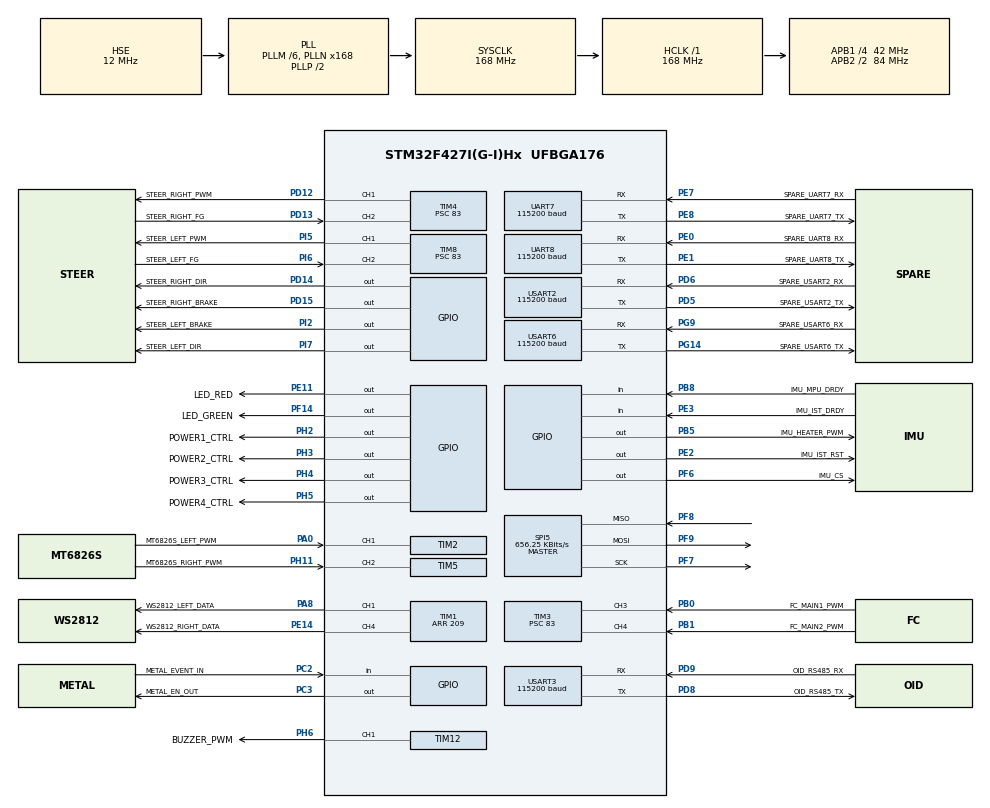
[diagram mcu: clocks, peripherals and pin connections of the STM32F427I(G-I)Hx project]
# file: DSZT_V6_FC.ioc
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Dma.Request0=TIM1_CH1
Dma.Request1=TIM1_CH4/TRIG/COM
Dma.TIM1_CH1.0.Direction=DMA_MEMORY_TO_PERIPH
Dma.TIM1_CH1.0.FIFOMode=DMA_FIFOMODE_DISABLE
Dma.TIM1_CH1.0.Instance=DMA2_Stream3
Dma.TIM1_CH1.0.MemDataAlignment=DMA_MDATAALIGN_HALFWORD
Dma.TIM1_CH1.0.MemInc=DMA_MINC_ENABLE
Dma.TIM1_CH1.0.Mode=DMA_NORMAL
Dma.TIM1_CH1.0.PeriphDataAlignment=DMA_PDATAALIGN_HALFWORD
Dma.TIM1_CH1.0.PeriphInc=DMA_PINC_DISABLE
Dma.TIM1_CH1.0.Priority=DMA_PRIORITY_HIGH
Dma.TIM1_CH4/TRIG/COM.1.Direction=DMA_MEMORY_TO_PERIPH
Dma.TIM1_CH4/TRIG/COM.1.FIFOMode=DMA_FIFOMODE_DISABLE
Dma.TIM1_CH4/TRIG/COM.1.Instance=DMA2_Stream4
Dma.TIM1_CH4/TRIG/COM.1.MemDataAlignment=DMA_MDATAALIGN_HALFWORD
Dma.TIM1_CH4/TRIG/COM.1.MemInc=DMA_MINC_ENABLE
Dma.TIM1_CH4/TRIG/COM.1.Mode=DMA_NORMAL
Dma.TIM1_CH4/TRIG/COM.1.PeriphDataAlignment=DMA_PDATAALIGN_HALFWORD
Dma.TIM1_CH4/TRIG/COM.1.PeriphInc=DMA_PINC_DISABLE
Dma.TIM1_CH4/TRIG/COM.1.Priority=DMA_PRIORITY_HIGH
FREERTOS.INCLUDE_vTaskDelayUntil=1
FREERTOS.Tasks01=defaultTask,0,1024,StartDefaultTask,Default,NULL,Dynamic,NULL,NULL
FREERTOS.configENABLE_FPU=1
FREERTOS.configMAX_TASK_NAME_LEN=32
FREERTOS.configTOTAL_HEAP_SIZE=30000
FREERTOS.configUSE_COUNTING_SEMAPHORES=1
FREERTOS.configUSE_POSIX_ERRNO=0
FREERTOS.configUSE_TIMERS=0
Mcu.Family=STM32F4
Mcu.Name=STM32F427I(G-I)Hx
Mcu.Package=UFBGA176
NVIC.DMA2_Stream3_IRQn=true\:5\:0\:false\:false\:true\:true\:true\:true\:true
NVIC.DMA2_Stream4_IRQn=true\:5\:0\:false\:false\:true\:true\:true\:true\:true
NVIC.PriorityGroup=NVIC_PRIORITYGROUP_4
NVIC.TIM2_IRQn=true\:5\:0\:false\:false\:true\:true\:true\:true\:true
NVIC.TIM3_IRQn=true\:5\:0\:false\:false\:true\:true\:true\:true\:true
NVIC.TIM4_IRQn=true\:5\:0\:false\:false\:true\:true\:true\:true\:true
NVIC.TIM5_IRQn=true\:5\:0\:false\:false\:true\:true\:true\:true\:true
NVIC.TIM6_DAC_IRQn=true\:15\:0\:false\:false\:true\:false\:false\:true\:true
NVIC.TIM8_CC_IRQn=true\:5\:0\:false\:false\:true\:true\:true\:true\:true
NVIC.TimeBase=TIM6_DAC_IRQn
NVIC.TimeBaseIP=TIM6
NVIC.UART7_IRQn=true\:5\:0\:false\:false\:true\:true\:true\:true\:true
NVIC.USART3_IRQn=true\:5\:0\:false\:false\:true\:true\:true\:true\:true
PA0/WKUP.GPIO_Label=MT6826S_LEFT_PWM
PA0/WKUP.Signal=S_TIM2_CH1_ETR
PA13.Mode=Serial_Wire
PA13.Signal=SYS_JTMS-SWDIO
PA14.Mode=Serial_Wire
PA14.Signal=SYS_JTCK-SWCLK
PA8.GPIO_Label=WS2812_LEFT_DATA
PA8.GPIO_Speed=GPIO_SPEED_FREQ_VERY_HIGH
PA8.Signal=S_TIM1_CH1
PB0.GPIO_Label=FC_MAIN1_PWM
PB0.GPIO_PuPd=GPIO_PULLDOWN
PB0.Signal=S_TIM3_CH3
PB1.GPIO_Label=FC_MAIN2_PWM
PB1.GPIO_PuPd=GPIO_PULLDOWN
PB1.Signal=S_TIM3_CH4
PB5.GPIO_Label=IMU_HEATER_PWM
PB5.GPIO_OutputLevel=GPIO_PIN_RESET
PB5.Signal=GPIO_Output
PB8.GPIO_Label=IMU_MPU_DRDY
PB8.Signal=GPIO_Input
PC2.GPIO_Label=METAL_EVENT_IN
PC2.Signal=GPIO_Input
PC3.GPIO_Label=METAL_EN_OUT
PC3.GPIO_OutputLevel=GPIO_PIN_RESET
PC3.Signal=GPIO_Output
PD12.GPIO_Label=STEER_RIGHT_PWM
PD12.Signal=S_TIM4_CH1
PD13.GPIO_Label=STEER_RIGHT_FG
PD13.Signal=S_TIM4_CH2
PD14.GPIO_Label=STEER_RIGHT_DIR
PD14.GPIO_ModeDefaultOutputPP=GPIO_MODE_OUTPUT_OD
PD14.GPIO_PuPd=GPIO_NOPULL
PD14.Signal=GPIO_Output
PD15.GPIO_Label=STEER_RIGHT_BRAKE
PD15.GPIO_ModeDefaultOutputPP=GPIO_MODE_OUTPUT_OD
PD15.GPIO_PuPd=GPIO_NOPULL
PD15.Signal=GPIO_Output
PD5.GPIO_Label=SPARE_USART2_TX
PD5.Mode=Asynchronous
PD5.Signal=USART2_TX
PD6.GPIO_Label=SPARE_USART2_RX
PD6.Mode=Asynchronous
PD6.Signal=USART2_RX
PD8.GPIO_Label=OID_RS485_TX
PD8.Mode=Asynchronous
PD8.Signal=USART3_TX
PD9.GPIO_Label=OID_RS485_RX
PD9.Mode=Asynchronous
PD9.Signal=USART3_RX
PE0.GPIO_Label=SPARE_UART8_RX
PE0.Mode=Asynchronous
PE0.Signal=UART8_RX
PE1.GPIO_Label=SPARE_UART8_TX
PE1.Mode=Asynchronous
PE1.Signal=UART8_TX
PE11.GPIO_Label=LED_RED
PE11.GPIO_OutputLevel=GPIO_PIN_SET
PE11.Signal=GPIO_Output
PE14.GPIO_Label=WS2812_RIGHT_DATA
PE14.GPIO_Speed=GPIO_SPEED_FREQ_VERY_HIGH
PE14.Signal=S_TIM1_CH4
PE2.GPIO_Label=IMU_IST_RST
PE2.GPIO_OutputLevel=GPIO_PIN_SET
PE2.Signal=GPIO_Output
PE3.GPIO_Label=IMU_IST_DRDY
PE3.Signal=GPIO_Input
PE7.GPIO_Label=SPARE_UART7_RX
PE7.Mode=Asynchronous
PE7.Signal=UART7_RX
PE8.GPIO_Label=SPARE_UART7_TX
PE8.Mode=Asynchronous
PE8.Signal=UART7_TX
PF14.GPIO_Label=LED_GREEN
PF14.GPIO_OutputLevel=GPIO_PIN_SET
PF14.Signal=GPIO_Output
PF6.GPIO_Label=IMU_CS
PF6.GPIO_OutputLevel=GPIO_PIN_SET
PF6.Signal=GPIO_Output
PF7.Mode=Full_Duplex_Master
PF7.Signal=SPI5_SCK
PF8.Mode=Full_Duplex_Master
PF8.Signal=SPI5_MISO
PF9.Mode=Full_Duplex_Master
PF9.Signal=SPI5_MOSI
PG14.GPIO_Label=SPARE_USART6_TX
PG14.Mode=Asynchronous
PG14.Signal=USART6_TX
PG9.GPIO_Label=SPARE_USART6_RX
PG9.Mode=Asynchronous
PG9.Signal=USART6_RX
PH0/OSC_IN.Mode=HSE-External-Oscillator
PH0/OSC_IN.Signal=RCC_OSC_IN
PH1/OSC_OUT.Mode=HSE-External-Oscillator
PH1/OSC_OUT.Signal=RCC_OSC_OUT
PH11.GPIO_Label=MT6826S_RIGHT_PWM
PH11.Signal=S_TIM5_CH2
PH2.GPIO_Label=POWER1_CTRL
PH2.PinState=GPIO_PIN_SET
PH2.Signal=GPIO_Output
PH3.GPIO_Label=POWER2_CTRL
PH3.PinState=GPIO_PIN_SET
PH3.Signal=GPIO_Output
PH4.GPIO_Label=POWER3_CTRL
PH4.PinState=GPIO_PIN_SET
PH4.Signal=GPIO_Output
PH5.GPIO_Label=POWER4_CTRL
PH5.PinState=GPIO_PIN_SET
PH5.Signal=GPIO_Output
PH6.GPIO_Label=BUZZER_PWM
PH6.GPIO_Speed=GPIO_SPEED_FREQ_HIGH
PH6.Signal=S_TIM12_CH1
PI2.GPIO_Label=STEER_LEFT_BRAKE
PI2.GPIO_ModeDefaultOutputPP=GPIO_MODE_OUTPUT_OD
PI2.GPIO_PuPd=GPIO_NOPULL
PI2.Signal=GPIO_Output
PI5.GPIO_Label=STEER_LEFT_PWM
PI5.Signal=S_TIM8_CH1
PI6.GPIO_Label=STEER_LEFT_FG
PI6.Signal=S_TIM8_CH2
PI7.GPIO_Label=STEER_LEFT_DIR
PI7.GPIO_ModeDefaultOutputPP=GPIO_MODE_OUTPUT_OD
PI7.GPIO_PuPd=GPIO_NOPULL
PI7.Signal=GPIO_Output
ProjectManager.HeapSize=0x200
ProjectManager.StackSize=0x400
ProjectManager.TargetToolchain=MDK-ARM V5.32
RCC.48MHZClocksFreq_Value=48000000
RCC.AHBFreq_Value=168000000
RCC.APB1CLKDivider=RCC_HCLK_DIV4
RCC.APB1Freq_Value=42000000
RCC.APB1TimFreq_Value=84000000
RCC.APB2CLKDivider=RCC_HCLK_DIV2
RCC.APB2Freq_Value=84000000
RCC.APB2TimFreq_Value=168000000
RCC.CortexFreq_Value=168000000
RCC.HCLKFreq_Value=168000000
RCC.HSE_VALUE=12000000
RCC.HSI_VALUE=16000000
RCC.LSE_VALUE=32768
RCC.PLLM=6
RCC.PLLN=168
RCC.PLLQ=7
RCC.PLLSourceVirtual=RCC_PLLSOURCE_HSE
RCC.SYSCLKFreq_VALUE=168000000
RCC.SYSCLKSource=RCC_SYSCLKSOURCE_PLLCLK
RCC.VCOOutputFreq_Value=336000000
SH.S_TIM12_CH1.0=TIM12_CH1,PWM Generation1 CH1
SH.S_TIM1_CH1.0=TIM1_CH1,PWM Generation1 CH1
SH.S_TIM1_CH4.0=TIM1_CH4,PWM Generation4 CH4
SH.S_TIM2_CH1_ETR.0=TIM2_CH1,Input_Capture1_from_TI1
SH.S_TIM3_CH3.0=TIM3_CH3,Input_Capture3_from_TI3
SH.S_TIM3_CH4.0=TIM3_CH4,Input_Capture4_from_TI4
SH.S_TIM4_CH1.0=TIM4_CH1,PWM Generation1 CH1
SH.S_TIM4_CH2.0=TIM4_CH2,Input_Capture2_from_TI2
SH.S_TIM5_CH2.0=TIM5_CH2,Input_Capture2_from_TI2
SH.S_TIM8_CH1.0=TIM8_CH1,PWM Generation1 CH1
SH.S_TIM8_CH2.0=TIM8_CH2,Input_Capture2_from_TI2
SPI5.BaudRatePrescaler=SPI_BAUDRATEPRESCALER_128
SPI5.CalculateBaudRate=656.25 KBits/s
SPI5.Direction=SPI_DIRECTION_2LINES
SPI5.Mode=SPI_MODE_MASTER
SPI5.VirtualType=VM_MASTER
TIM1.Channel-PWM\ Generation1\ CH1=TIM_CHANNEL_1
TIM1.Channel-PWM\ Generation4\ CH4=TIM_CHANNEL_4
TIM1.Period=209
TIM12.AutoReloadPreload=TIM_AUTORELOAD_PRELOAD_DISABLE
TIM12.Channel-PWM\ Generation1\ CH1=TIM_CHANNEL_1
TIM12.ClockDivision=TIM_CLOCKDIVISION_DIV1
TIM12.CounterMode=TIM_COUNTERMODE_UP
TIM12.OCFastMode_PWM-PWM\ Generation1\ CH1=TIM_OCFAST_DISABLE
TIM12.Period=31110
TIM12.Prescaler=0
TIM12.Pulse-PWM\ Generation1\ CH1=0
TIM2.AutoReloadPreload=TIM_AUTORELOAD_PRELOAD_DISABLE
TIM2.Channel-Input_Capture1_from_TI1=TIM_CHANNEL_1
TIM2.ClockDivision=TIM_CLOCKDIVISION_DIV1
TIM2.CounterMode=TIM_COUNTERMODE_UP
TIM2.Period=4294967295
TIM2.Prescaler=83
TIM3.AutoReloadPreload=TIM_AUTORELOAD_PRELOAD_DISABLE
TIM3.Channel-Input_Capture3_from_TI3=TIM_CHANNEL_3
TIM3.Channel-Input_Capture4_from_TI4=TIM_CHANNEL_4
TIM3.ClockDivision=TIM_CLOCKDIVISION_DIV1
TIM3.CounterMode=TIM_COUNTERMODE_UP
TIM3.Period=65535
TIM3.Prescaler=83
TIM4.AutoReloadPreload=TIM_AUTORELOAD_PRELOAD_DISABLE
TIM4.Channel-Input_Capture2_from_TI2=TIM_CHANNEL_2
TIM4.Channel-PWM\ Generation1\ CH1=TIM_CHANNEL_1
TIM4.ClockDivision=TIM_CLOCKDIVISION_DIV1
TIM4.CounterMode=TIM_COUNTERMODE_UP
TIM4.OCFastMode_PWM-PWM\ Generation1\ CH1=TIM_OCFAST_DISABLE
TIM4.Period=39
TIM4.Prescaler=83
TIM4.Pulse-PWM\ Generation1\ CH1=40
TIM5.Channel-Input_Capture2_from_TI2=TIM_CHANNEL_2
TIM5.Period=4294967295
TIM5.Prescaler=83
TIM8.AutoReloadPreload=TIM_AUTORELOAD_PRELOAD_DISABLE
TIM8.Channel-Input_Capture2_from_TI2=TIM_CHANNEL_2
TIM8.Channel-PWM\ Generation1\ CH1=TIM_CHANNEL_1
TIM8.ClockDivision=TIM_CLOCKDIVISION_DIV1
TIM8.CounterMode=TIM_COUNTERMODE_UP
TIM8.OCFastMode_PWM-PWM\ Generation1\ CH1=TIM_OCFAST_DISABLE
TIM8.Period=39
TIM8.Prescaler=83
TIM8.Pulse-PWM\ Generation1\ CH1=40
UART7.BaudRate=115200
UART7.VirtualMode=Asynchronous
UART8.BaudRate=115200
UART8.VirtualMode=Asynchronous
USART2.BaudRate=115200
USART2.VirtualMode=VM_ASYNC
USART3.BaudRate=115200
USART3.VirtualMode=VM_ASYNC
USART6.BaudRate=115200
USART6.VirtualMode=VM_ASYNC
VP_FREERTOS_VS_CMSIS_V1.Mode=CMSIS_V1
VP_SYS_VS_tim6.Mode=TIM6
VP_TIM1_VS_ClockSourceINT.Mode=Internal
board=custom

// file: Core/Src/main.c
/* USER CODE BEGIN Header */
/**
  ******************************************************************************
  * @file           : main.c
  * @brief          : Main program body
  ******************************************************************************
  * @attention
  *
  * Copyright (c) 2026 STMicroelectronics.
  * All rights reserved.
  *
  * This software is licensed under terms that can be found in the LICENSE file
  * in the root directory of this software component.
  * If no LICENSE file comes with this software, it is provided AS-IS.
  *
  ******************************************************************************
  */
/* USER CODE END Header */
#include "main.h"
#include "cmsis_os.h"
#include "dma.h"
#include "spi.h"
#include "tim.h"
#include "usart.h"
#include "gpio.h"

/* USER CODE BEGIN Includes */
#include "robot.h"
/* USER CODE END Includes */

void SystemClock_Config(void);
void MX_FREERTOS_Init(void);

int main(void)
{

  /* MCU Configuration--------------------------------------------------------*/

  /* Reset of all peripherals, Initializes the Flash interface and the Systick. */
  HAL_Init();

  /* Configure the system clock */
  SystemClock_Config();

  /* Initialize all configured peripherals */
  MX_GPIO_Init();
  MX_DMA_Init();
  MX_SPI5_Init();
  MX_TIM1_Init();
  MX_TIM2_Init();
  MX_TIM3_Init();
  MX_TIM4_Init();
  MX_TIM5_Init();
  MX_TIM8_Init();
  MX_TIM12_Init();
  MX_UART7_Init();
  MX_UART8_Init();
  MX_USART2_UART_Init();
  MX_USART3_UART_Init();
  MX_USART6_UART_Init();
  /* USER CODE BEGIN 2 */
  RobotInit();
  /* USER CODE END 2 */

  /* Call init function for freertos objects (in cmsis_os2.c) */
  MX_FREERTOS_Init();

  /* Start scheduler */
  osKernelStart();

  /* We should never get here as control is now taken by the scheduler */

  /* Infinite loop */
  while (1)
  {

  }
}

void SystemClock_Config(void)
{
  RCC_OscInitTypeDef RCC_OscInitStruct = {0};
  RCC_ClkInitTypeDef RCC_ClkInitStruct = {0};

  /** Configure the main internal regulator output voltage
  */
  __HAL_RCC_PWR_CLK_ENABLE();
  __HAL_PWR_VOLTAGESCALING_CONFIG(PWR_REGULATOR_VOLTAGE_SCALE1);

  /** Initializes the RCC Oscillators according to the specified parameters
  * in the RCC_OscInitTypeDef structure.
  */
  RCC_OscInitStruct.OscillatorType = RCC_OSCILLATORTYPE_HSE;
  RCC_OscInitStruct.HSEState = RCC_HSE_ON;
  RCC_OscInitStruct.PLL.PLLState = RCC_PLL_ON;
  RCC_OscInitStruct.PLL.PLLSource = RCC_PLLSOURCE_HSE;
  RCC_OscInitStruct.PLL.PLLM = 6;
  RCC_OscInitStruct.PLL.PLLN = 168;
  RCC_OscInitStruct.PLL.PLLP = RCC_PLLP_DIV2;
  RCC_OscInitStruct.PLL.PLLQ = 7;
  if (HAL_RCC_OscConfig(&RCC_OscInitStruct) != HAL_OK)
  {
    Error_Handler();
  }

  /** Initializes the CPU, AHB and APB buses clocks
  */
  RCC_ClkInitStruct.ClockType = RCC_CLOCKTYPE_HCLK|RCC_CLOCKTYPE_SYSCLK
                              |RCC_CLOCKTYPE_PCLK1|RCC_CLOCKTYPE_PCLK2;
  RCC_ClkInitStruct.SYSCLKSource = RCC_SYSCLKSOURCE_PLLCLK;
  RCC_ClkInitStruct.AHBCLKDivider = RCC_SYSCLK_DIV1;
  RCC_ClkInitStruct.APB1CLKDivider = RCC_HCLK_DIV4;
  RCC_ClkInitStruct.APB2CLKDivider = RCC_HCLK_DIV2;

  if (HAL_RCC_ClockConfig(&RCC_ClkInitStruct, FLASH_LATENCY_5) != HAL_OK)
  {
    Error_Handler();
  }
}

void HAL_TIM_PeriodElapsedCallback(TIM_HandleTypeDef *htim)
{
  if (htim->Instance == TIM6)
  {
    HAL_IncTick();
  }
}

void Error_Handler(void)
{
  __disable_irq();
  while (1)
  {
  }
}

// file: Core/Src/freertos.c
/* USER CODE BEGIN Header */
/**
  ******************************************************************************
  * File Name          : freertos.c
  * Description        : Code for freertos applications
  ******************************************************************************
  * @attention
  *
  * Copyright (c) 2026 STMicroelectronics.
  * All rights reserved.
  *
  * This software is licensed under terms that can be found in the LICENSE file
  * in the root directory of this software component.
  * If no LICENSE file comes with this software, it is provided AS-IS.
  *
  ******************************************************************************
  */
/* USER CODE END Header */

#include "FreeRTOS.h"
#include "task.h"
#include "main.h"
#include "cmsis_os.h"

/* USER CODE BEGIN Includes */
#include "robot.h"
/* USER CODE END Includes */

osThreadId defaultTaskHandle;

void StartDefaultTask(void const * argument);

void MX_FREERTOS_Init(void); /* (MISRA C 2004 rule 8.1) */

/* GetIdleTaskMemory prototype (linked to static allocation support) */
void vApplicationGetIdleTaskMemory( StaticTask_t **ppxIdleTaskTCBBuffer, StackType_t **ppxIdleTaskStackBuffer, uint32_t *pulIdleTaskStackSize );

/* USER CODE BEGIN GET_IDLE_TASK_MEMORY */
static StaticTask_t xIdleTaskTCBBuffer;
static StackType_t xIdleStack[configMINIMAL_STACK_SIZE];

void vApplicationGetIdleTaskMemory( StaticTask_t **ppxIdleTaskTCBBuffer, StackType_t **ppxIdleTaskStackBuffer, uint32_t *pulIdleTaskStackSize )
{
  *ppxIdleTaskTCBBuffer = &xIdleTaskTCBBuffer;
  *ppxIdleTaskStackBuffer = &xIdleStack[0];
  *pulIdleTaskStackSize = configMINIMAL_STACK_SIZE;
  /* place for user code */
}
/* USER CODE END GET_IDLE_TASK_MEMORY */

void MX_FREERTOS_Init(void) {

  /* Create the thread(s) */
  /* definition and creation of defaultTask */
  osThreadDef(defaultTask, StartDefaultTask, osPriorityNormal, 0, 1024);
  defaultTaskHandle = osThreadCreate(osThread(defaultTask), NULL);

}

void StartDefaultTask(void const * argument)
{
  /* USER CODE BEGIN StartDefaultTask */
  /* Infinite loop */
  for(;;)
  {
    RobotTask();
    osDelay(1);
  }
  /* USER CODE END StartDefaultTask */
}
